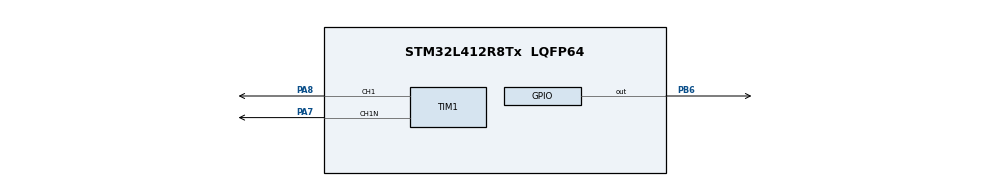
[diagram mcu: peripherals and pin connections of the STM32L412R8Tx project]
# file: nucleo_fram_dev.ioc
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Mcu.Family=STM32L4
Mcu.Name=STM32L412R8Tx
Mcu.Package=LQFP64
NVIC.PriorityGroup=NVIC_PRIORITYGROUP_4
PA7.Mode=PWM Generation1 CH1 CH1N
PA7.Signal=TIM1_CH1N
PA8.Signal=S_TIM1_CH1
PB13.Signal=SPI2_SCK
PB14.Signal=SPI2_MISO
PB15.Signal=SPI2_MOSI
PB6.Signal=GPIO_Output
ProjectManager.HeapSize=0x200
ProjectManager.StackSize=0x400
ProjectManager.TargetToolchain=STM32CubeIDE
RCC.ADCFreq_Value=4000000
RCC.HSE_VALUE=8000000
RCC.HSI48_VALUE=48000000
RCC.HSI_VALUE=16000000
RCC.LSE_VALUE=32768
RCC.MSI_VALUE=4000000
RCC.USBFreq_Value=4000000
RCC.VCOOutputFreq_Value=32000000
SH.S_TIM1_CH1.0=TIM1_CH1,PWM Generation1 CH1 CH1N
TIM1.Channel-PWM\ Generation1\ CH1\ CH1N=TIM_CHANNEL_1
TIM1.OCIdleState_1=TIM_OCIDLESTATE_RESET
TIM1.OCNIdleState_1=TIM_OCNIDLESTATE_SET
VP_TIM1_VS_ClockSourceINT.Mode=Internal
board=custom

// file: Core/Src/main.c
/* USER CODE BEGIN Header */
/**
  ******************************************************************************
  * @file           : main.c
  * @brief          : Main program body
  ******************************************************************************
  * @attention
  *
  * Copyright (c) 2024 STMicroelectronics.
  * All rights reserved.
  *
  * This software is licensed under terms that can be found in the LICENSE file
  * in the root directory of this software component.
  * If no LICENSE file comes with this software, it is provided AS-IS.
  *
  ******************************************************************************
  */
/* USER CODE END Header */
#include "main.h"

void SystemClock_Config(void);
static void MX_GPIO_Init(void);
static void MX_TIM1_Init(void);

int main(void)
{

  /* MCU Configuration--------------------------------------------------------*/

  /* Reset of all peripherals, Initializes the Flash interface and the Systick. */
  LL_APB2_GRP1_EnableClock(LL_APB2_GRP1_PERIPH_SYSCFG);
  LL_APB1_GRP1_EnableClock(LL_APB1_GRP1_PERIPH_PWR);

  /* System interrupt init*/
  NVIC_SetPriorityGrouping(NVIC_PRIORITYGROUP_4);

  /* SysTick_IRQn interrupt configuration */
  NVIC_SetPriority(SysTick_IRQn, NVIC_EncodePriority(NVIC_GetPriorityGrouping(),15, 0));

  /* Configure the system clock */
  SystemClock_Config();

  /* Initialize all configured peripherals */
  MX_GPIO_Init();
  MX_TIM1_Init();
  /* USER CODE BEGIN 2 */

  LL_TIM_EnableCounter(TIM1);
  LL_TIM_CC_EnableChannel(TIM1, LL_TIM_CHANNEL_CH1);
    // LL_TIM_CC_EnableChannel(TIM1, (LL_TIM_CHANNEL_CH1 || LL_TIM_CHANNEL_CH1N));
    LL_TIM_OC_SetCompareCH1(TIM1, 500);

  /* USER CODE END 2 */

  /* Infinite loop */
  while (1)
  {

  }
}

void SystemClock_Config(void)
{
  LL_FLASH_SetLatency(LL_FLASH_LATENCY_0);
  while(LL_FLASH_GetLatency()!= LL_FLASH_LATENCY_0)
  {
  }
  LL_PWR_SetRegulVoltageScaling(LL_PWR_REGU_VOLTAGE_SCALE1);
  while (LL_PWR_IsActiveFlag_VOS() != 0)
  {
  }
  LL_RCC_MSI_Enable();

   /* Wait till MSI is ready */
  while(LL_RCC_MSI_IsReady() != 1)
  {

  }
  LL_RCC_MSI_EnableRangeSelection();
  LL_RCC_MSI_SetRange(LL_RCC_MSIRANGE_6);
  LL_RCC_MSI_SetCalibTrimming(0);
  LL_RCC_SetSysClkSource(LL_RCC_SYS_CLKSOURCE_MSI);

   /* Wait till System clock is ready */
  while(LL_RCC_GetSysClkSource() != LL_RCC_SYS_CLKSOURCE_STATUS_MSI)
  {

  }
  LL_RCC_SetAHBPrescaler(LL_RCC_SYSCLK_DIV_1);
  LL_RCC_SetAPB1Prescaler(LL_RCC_APB1_DIV_1);
  LL_RCC_SetAPB2Prescaler(LL_RCC_APB2_DIV_1);

  LL_Init1msTick(4000000);

  LL_SetSystemCoreClock(4000000);
}

static void MX_TIM1_Init(void)
{

  LL_TIM_InitTypeDef TIM_InitStruct = {0};
  LL_TIM_OC_InitTypeDef TIM_OC_InitStruct = {0};
  LL_TIM_BDTR_InitTypeDef TIM_BDTRInitStruct = {0};

  LL_GPIO_InitTypeDef GPIO_InitStruct = {0};

  /* Peripheral clock enable */
  LL_APB2_GRP1_EnableClock(LL_APB2_GRP1_PERIPH_TIM1);

  TIM_InitStruct.Prescaler = 0;
  TIM_InitStruct.CounterMode = LL_TIM_COUNTERMODE_UP;
  TIM_InitStruct.Autoreload = 65535;
  TIM_InitStruct.ClockDivision = LL_TIM_CLOCKDIVISION_DIV1;
  TIM_InitStruct.RepetitionCounter = 0;
  LL_TIM_Init(TIM1, &TIM_InitStruct);
  LL_TIM_DisableARRPreload(TIM1);
  LL_TIM_SetClockSource(TIM1, LL_TIM_CLOCKSOURCE_INTERNAL);
  LL_TIM_OC_EnablePreload(TIM1, LL_TIM_CHANNEL_CH1);
  TIM_OC_InitStruct.OCMode = LL_TIM_OCMODE_PWM1;
  TIM_OC_InitStruct.OCState = LL_TIM_OCSTATE_DISABLE;
  TIM_OC_InitStruct.OCNState = LL_TIM_OCSTATE_DISABLE;
  TIM_OC_InitStruct.CompareValue = 0;
  TIM_OC_InitStruct.OCPolarity = LL_TIM_OCPOLARITY_HIGH;
  TIM_OC_InitStruct.OCNPolarity = LL_TIM_OCPOLARITY_HIGH;
  TIM_OC_InitStruct.OCIdleState = LL_TIM_OCIDLESTATE_LOW;
  TIM_OC_InitStruct.OCNIdleState = LL_TIM_OCIDLESTATE_HIGH;
  LL_TIM_OC_Init(TIM1, LL_TIM_CHANNEL_CH1, &TIM_OC_InitStruct);
  LL_TIM_OC_DisableFast(TIM1, LL_TIM_CHANNEL_CH1);
  LL_TIM_SetOCRefClearInputSource(TIM1, LL_TIM_OCREF_CLR_INT_NC);
  LL_TIM_DisableExternalClock(TIM1);
  LL_TIM_ConfigETR(TIM1, LL_TIM_ETR_POLARITY_NONINVERTED, LL_TIM_ETR_PRESCALER_DIV1, LL_TIM_ETR_FILTER_FDIV1);
  LL_TIM_SetTriggerOutput(TIM1, LL_TIM_TRGO_RESET);
  LL_TIM_SetTriggerOutput2(TIM1, LL_TIM_TRGO2_RESET);
  LL_TIM_DisableMasterSlaveMode(TIM1);
  TIM_BDTRInitStruct.OSSRState = LL_TIM_OSSR_DISABLE;
  TIM_BDTRInitStruct.OSSIState = LL_TIM_OSSI_DISABLE;
  TIM_BDTRInitStruct.LockLevel = LL_TIM_LOCKLEVEL_OFF;
  TIM_BDTRInitStruct.DeadTime = 0;
  TIM_BDTRInitStruct.BreakState = LL_TIM_BREAK_DISABLE;
  TIM_BDTRInitStruct.BreakPolarity = LL_TIM_BREAK_POLARITY_HIGH;
  TIM_BDTRInitStruct.BreakFilter = LL_TIM_BREAK_FILTER_FDIV1;
  TIM_BDTRInitStruct.Break2State = LL_TIM_BREAK2_DISABLE;
  TIM_BDTRInitStruct.Break2Polarity = LL_TIM_BREAK2_POLARITY_HIGH;
  TIM_BDTRInitStruct.Break2Filter = LL_TIM_BREAK2_FILTER_FDIV1;
  TIM_BDTRInitStruct.AutomaticOutput = LL_TIM_AUTOMATICOUTPUT_DISABLE;
  LL_TIM_BDTR_Init(TIM1, &TIM_BDTRInitStruct);
  LL_AHB2_GRP1_EnableClock(LL_AHB2_GRP1_PERIPH_GPIOA);
  /**TIM1 GPIO Configuration
  PA7   ------> TIM1_CH1N
  PA8   ------> TIM1_CH1
  */
  GPIO_InitStruct.Pin = LL_GPIO_PIN_7|LL_GPIO_PIN_8;
  GPIO_InitStruct.Mode = LL_GPIO_MODE_ALTERNATE;
  GPIO_InitStruct.Speed = LL_GPIO_SPEED_FREQ_LOW;
  GPIO_InitStruct.OutputType = LL_GPIO_OUTPUT_PUSHPULL;
  GPIO_InitStruct.Pull = LL_GPIO_PULL_NO;
  GPIO_InitStruct.Alternate = LL_GPIO_AF_1;
  LL_GPIO_Init(GPIOA, &GPIO_InitStruct);

}

static void MX_GPIO_Init(void)
{
  LL_GPIO_InitTypeDef GPIO_InitStruct = {0};

  /* GPIO Ports Clock Enable */
  LL_AHB2_GRP1_EnableClock(LL_AHB2_GRP1_PERIPH_GPIOA);
  LL_AHB2_GRP1_EnableClock(LL_AHB2_GRP1_PERIPH_GPIOB);

  /**/
  LL_GPIO_ResetOutputPin(GPIOB, LL_GPIO_PIN_6);

  /**/
  GPIO_InitStruct.Pin = LL_GPIO_PIN_13|LL_GPIO_PIN_14|LL_GPIO_PIN_15;
  GPIO_InitStruct.Mode = LL_GPIO_MODE_ALTERNATE;
  GPIO_InitStruct.Speed = LL_GPIO_SPEED_FREQ_VERY_HIGH;
  GPIO_InitStruct.OutputType = LL_GPIO_OUTPUT_PUSHPULL;
  GPIO_InitStruct.Pull = LL_GPIO_PULL_NO;
  GPIO_InitStruct.Alternate = LL_GPIO_AF_5;
  LL_GPIO_Init(GPIOB, &GPIO_InitStruct);

  /**/
  GPIO_InitStruct.Pin = LL_GPIO_PIN_6;
  GPIO_InitStruct.Mode = LL_GPIO_MODE_OUTPUT;
  GPIO_InitStruct.Speed = LL_GPIO_SPEED_FREQ_LOW;
  GPIO_InitStruct.OutputType = LL_GPIO_OUTPUT_PUSHPULL;
  GPIO_InitStruct.Pull = LL_GPIO_PULL_NO;
  LL_GPIO_Init(GPIOB, &GPIO_InitStruct);

}

void Error_Handler(void)
{
  __disable_irq();
  while (1)
  {
  }
}
